# PIC32CZ4010CA80144 register map
Vendor: Microchip Technology; Series: PIC32CZCA80; File version: 0
CPU: CM7 r1p1, little endian, MPU, FPU, double-precision FPU, I-cache, D-cache, ITCM, DTCM, 3 interrupt priority bits, 222 interrupts
Registers are 32-bit, read-write, reset 0x0 unless marked. A register's access mark holds for its fields unless they carry their own. Offsets are from the block's base; [hi:lo] are bit positions; {n}, {i} and the like mark numbered series; <NAME> marks a mode.

## FREQM — Frequency Meter
Base 0x44060000
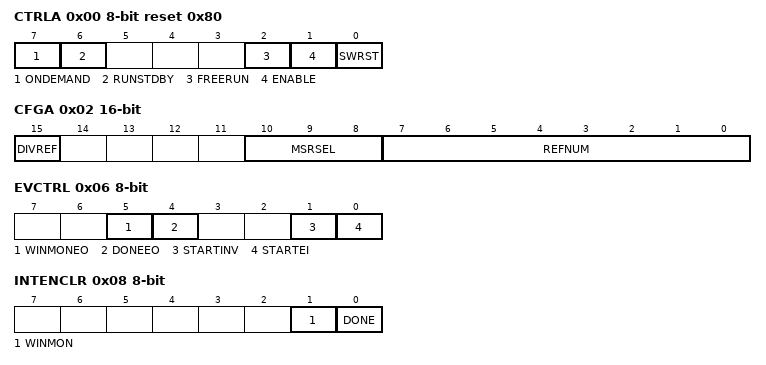
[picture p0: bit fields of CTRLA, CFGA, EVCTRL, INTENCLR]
0x00 CTRLA 8-bit reset 0x80 — Control A Register
  [7] ONDEMAND — On Demand Control
  [6] RUNSTDBY — Run In Standby
  [2] FREERUN — Free Running Mode
  [1] ENABLE
  [0] SWRST — Software Reset
0x01 CTRLB 8-bit wo — Control B Register
  [0] START — Start Measurement
0x02 CFGA 16-bit — Config A Register
  [15] DIVREF — Divide Reference Clock
    0=DIV1 (The reference clock is divided by 1); 1=DIV8 (The reference clock is divided by 8)
  [10:8] MSRSEL — Measurement Clock Selection
    0=GCLK (GCLK Input Clock); 1=CPU (CPU Input Clock)
  [7:0] REFNUM — Number of Reference Clock Cycles
0x04 CTRLC 8-bit — Control C Register
  [2:0] WINMODE — Window Monitor Mode
    0=DISABLE (No window mode (default)); 1=MODE1 (VALUE > WINLT); 2=MODE2 (VALUE < WINUT); 3=MODE3 (WINLT < VALUE < WINUT); 4=MODE4 (!(WINLT < VALUE < WINUT))
0x06 EVCTRL 8-bit — Event Control Register
  [5] WINMONEO — Window Monitor Event Out
  [4] DONEEO — Measurement Done Event Out
  [1] STARTINV — Start Measurement Event Invert Enable
  [0] STARTEI — Start Measurement Event Input Enable
0x08 INTENCLR 8-bit write-1-clears — Interrupt Enable Clear Register
  [1] WINMON — Window Monitor Interrupt Disable
  [0] DONE — Measurement Done Interrupt Disable
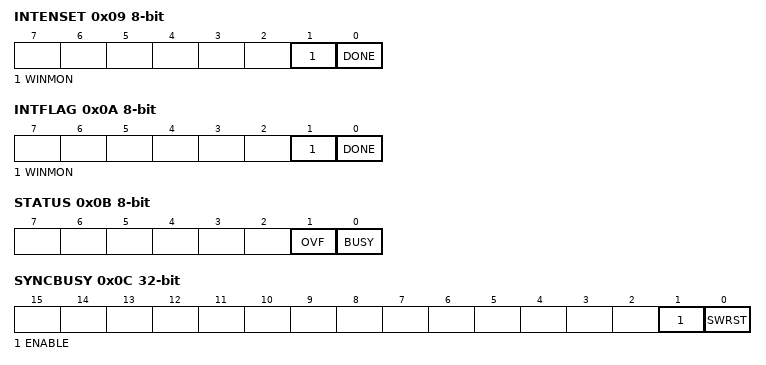
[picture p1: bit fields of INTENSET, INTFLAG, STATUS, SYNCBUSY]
0x09 INTENSET 8-bit write-1-sets — Interrupt Enable Set Register
  [1] WINMON — Window Monitor Interrupt Enable
  [0] DONE — Measurement Done Interrupt Enable
0x0A INTFLAG 8-bit write-1-clears — Interrupt Flag Register
  [1] WINMON — Window Monitor
  [0] DONE — Measurement Done
0x0B STATUS 8-bit
  [1] OVF — Sticky Count Value Overflow
  [0] BUSY — FREQM Status
0x0C SYNCBUSY ro — Synchronization Busy Register
  [1] ENABLE
  [0] SWRST — Software Reset
0x10 VALUE ro — Count Value Register
  [23:0] VALUE — Measurement Value
0x20 WINLT — Window Monitor Lower Threshold
  [23:0] WINLT — Window Lower Threshold
0x24 WINUT — Window Monitor Upper Threshold
  [23:0] WINUT — Window Upper Threshold

## GCLK — Generic Clock Generator
Base 0x44050000
0x00 CTRLA 8-bit — Control
  [0] SWRST — Software Reset
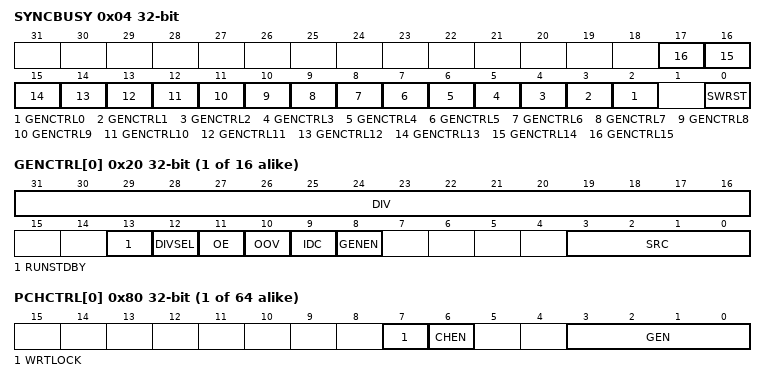
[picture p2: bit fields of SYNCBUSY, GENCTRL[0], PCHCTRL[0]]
0x04 SYNCBUSY ro — Synchronization Busy
  [n+2] GENCTRL{n} (n=0..15) — Generic Clock Generator Control {n} Synchronization Busy bit
  [0] SWRST — Software Reset Synchronization Busy bit
{0x20+4i} GENCTRL[{i}] (i=0..15) — Generic Clock Generator Control
  [31:16] DIV — Division Factor
  [13] RUNSTDBY — Run in Standby
  [12] DIVSEL — Divide Selection
    0=DIV1 (Divide input directly by divider factor); 1=DIV2 (Divide input by 2^(divider factor+ 1))
  [11] OE — Output Enable
  [10] OOV — Output Off Value
  [9] IDC — Improve Duty Cycle
  [8] GENEN — Generic Clock Generator Enable
  [3:0] SRC — Source Select
    0=XOSC (XOSC0 oscillator output); 1=GCLKIN (Generator input pad); 2=GCLKGEN1 (Generic clock generator 1 output); 3=OSCULP32K (OSCULP32K oscillator output); 4=XOSC32K (XOSC32K oscillator output); 5=DFLL (DFLL output); {v}=PLL0_{v-5} (PLL0 output {v-5}) (v=6..9); 10=PLL1_1 (Frac Divider PLL1 output 1); 11=PLL1_2 (Frac Divider PLL1 output 2); 12=PLL1_3 (PLL1 output 3); 13=PLL1_4 (PLL1 output 4)
{0x80+4i} PCHCTRL[{i}] (i=0..63) — Peripheral Clock Control
  [7] WRTLOCK — Write Lock
  [6] CHEN — Channel Enable
  [3:0] GEN — Generic Clock Generator
    {v}=GCLK{v} (Generic clock generator {v}) (v=0..15)

## ITM — Instrumentation Trace Macrocell
Base 0xE0041000; alternate view of ETM
{0x0+4i} PORT_BYTE_MODE[{i}] (i=0..31) wo — ITM Stimulus Port Registers
  [7:0] PORT
{0x0+4i} PORT_HWORD_MODE[{i}] (i=0..31) wo (alternate view of PORT_BYTE_MODE[{i}]) — ITM Stimulus Port Registers
  [15:0] PORT
{0x0+4i} PORT_WORD_MODE[{i}] (i=0..31) wo (alternate view of PORT_BYTE_MODE[{i}]) — ITM Stimulus Port Registers
  [31:0] PORT
0xE00 TER — ITM Trace Enable Register
0xE40 TPR — ITM Trace Privilege Register
  [3:0] PRIVMASK
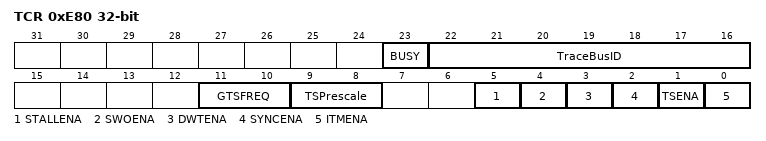
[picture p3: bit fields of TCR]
0xE80 TCR — ITM Trace Control Register
  [23] BUSY, [22:16] TraceBusID, [11:10] GTSFREQ, [9:8] TSPrescale, [5] STALLENA, [4] SWOENA, [3] DWTENA, [2] SYNCENA, [1] TSENA, [0] ITMENA
0xEF8 IWR wo — ITM Integration Write Register
  [0] ATVALIDM
0xEFC IRR ro — ITM Integration Read Register
  [0] ATREADYM
